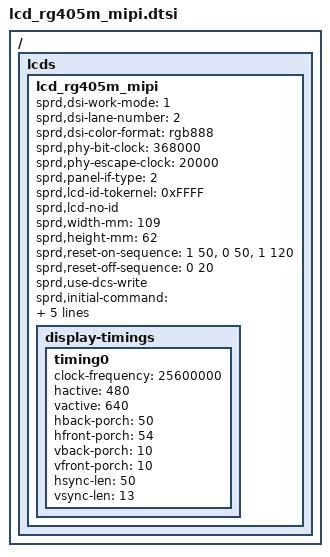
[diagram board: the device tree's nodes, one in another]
/*
 * Anbernic RG405M 640x480 2-lane MIPI LCD config dtsi for spreadtrum u-boot
 * (ST7701S-class panel, vendor name "lcd_d53e6ea8966_mipi_2lane_960X544").
 *
 * Init sequence extracted verbatim from the stock dtbo_a.img overlay
 * (device-extract/dtbo/dtbo1.dts, sprd,initial-command) — do not edit by hand.
 *
 * SPDX-License-Identifier: (GPL-2.0+ OR MIT)
 */

/ { lcds {
	lcd_rg405m_mipi: lcd_rg405m_mipi {
		sprd,dsi-work-mode = <1>;
		sprd,dsi-lane-number = <2>;
		sprd,dsi-color-format = "rgb888";
		sprd,phy-bit-clock = <368000>;
		sprd,phy-escape-clock = <20000>;
		sprd,panel-if-type = <2>;
		sprd,lcd-id-tokernel = <0xFFFF>;
		sprd,lcd-no-id;
		sprd,width-mm = <109>;
		sprd,height-mm = <62>;
		sprd,reset-on-sequence = <1 50>, <0 50>, <1 120>;
		sprd,reset-off-sequence = <0 20>;
		sprd,use-dcs-write;

		sprd,initial-command = [
			39 00 00 06 ff 77 01 00 00 13 23 00 00 02 ef 08
			39 00 00 06 ff 77 01 00 00 10 23 00 00 03 c0 4f
			03 23 00 00 03 c1 0c 02 23 00 00 03 c2 10 06 23
			00 00 02 c7 04 23 00 00 02 cc 38 39 00 00 11 b0
			40 16 1d 0e 12 06 0c 0a 09 25 00 03 00 3f 3f 1c
			39 00 00 11 b1 40 16 1e 0e 11 06 0c 08 09 26 00
			15 00 3f 3f 1c 39 00 00 06 ff 77 01 00 00 11 23
			00 00 02 b0 4d 23 00 00 02 b1 35 23 00 00 02 b2
			07 23 00 00 02 b3 80 23 00 00 02 b5 47 23 00 00
			02 b7 85 23 00 00 02 b8 20 23 00 00 02 b9 10 23
			00 00 02 bc 03 23 00 00 02 c0 89 23 00 00 02 c1
			78 23 00 00 02 c2 78 23 00 00 02 d0 88 39 00 00
			04 e0 00 00 02 39 00 00 0c e1 04 00 00 00 05 00
			00 00 00 20 20 39 00 00 0e e2 00 00 00 00 00 00
			00 00 00 00 00 00 00 39 00 00 05 e3 00 00 33 00
			23 00 00 03 e4 22 00 39 00 00 11 e5 04 5c a0 a0
			06 5c a0 a0 00 00 00 00 00 00 00 00 39 00 00 05
			e6 00 00 33 00 23 00 00 03 e7 22 00 39 00 00 11
			e8 05 5c a0 a0 07 5c a0 a0 00 00 00 00 00 00 00
			00 39 00 00 08 eb 02 00 40 40 00 00 00 23 00 00
			03 ec 00 00 39 00 00 11 ed fa 45 0b ff ff ff ff
			ff ff ff ff ff ff b0 54 af 39 00 00 07 ef 08 08
			08 45 3f 54 39 00 00 06 ff 77 01 00 00 00 23 00
			00 02 36 17 23 00 00 02 3a 77 13 c8 00 01 11 13
			0a 00 01 29
		];

		sprd,sleep-in-command = [
			13 0a 00 01 28
			13 78 00 01 10
		];

		sprd,sleep-out-command = [
			13 78 00 01 11
			13 64 00 01 29
		];

		display-timings {
			timing0: timing0 {
				clock-frequency = <25600000>;
				hactive = <480>;
				vactive = <640>;
				hback-porch = <50>;
				hfront-porch = <54>;
				vback-porch = <10>;
				vfront-porch = <10>;
				hsync-len = <50>;
				vsync-len = <13>;
			};
		};
	};
};};
